VERSION ""

NS_ :

BS_:

BU_:

BO_ 336 HEARTBEAT: 8 Vector__XXX
 SG_ State : 0|8@1+ (1,0) [0|0] "" Vector__XXX
 SG_ Counter : 8|8@1+ (1,0) [0|0] "" Vector__XXX

BO_ 337 ERRORS: 8 Vector__XXX
 SG_ BSPD_Error : 0|8@1+ (1,0) [0|0] "" Vector__XXX
 SG_ LowPressure_Error : 8|8@1+ (1,0) [0|0] "" Vector__XXX

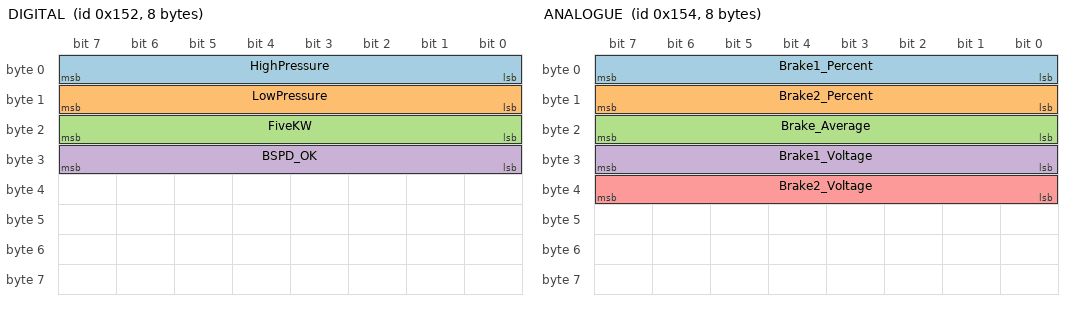
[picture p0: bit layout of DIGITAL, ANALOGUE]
BO_ 338 DIGITAL: 8 Vector__XXX
 SG_ HighPressure : 0|8@1+ (1,0) [0|0] "" Vector__XXX
 SG_ LowPressure : 8|8@1+ (1,0) [0|0] "" Vector__XXX
 SG_ FiveKW : 16|8@1+ (1,0) [0|0] "" Vector__XXX
 SG_ BSPD_OK : 24|8@1+ (1,0) [0|0] "" Vector__XXX

BO_ 340 ANALOGUE: 8 Vector__XXX
 SG_ Brake1_Percent : 0|8@1+ (1,0) [0|0] "" Vector__XXX
 SG_ Brake2_Percent : 8|8@1+ (1,0) [0|0] "" Vector__XXX
 SG_ Brake_Average : 16|8@1+ (1,0) [0|0] "" Vector__XXX
 SG_ Brake1_Voltage : 24|8@1+ (0.1,0) [0|0] "" Vector__XXX
 SG_ Brake2_Voltage : 32|8@1+ (0.1,0) [0|0] "" Vector__XXX
